# C7X256V0_CLEC_CLEC register map
Vendor: Texas Instruments
Peripheral module from a debugger description file (folder J722S).
Registers are 32-bit, read-only, reset values left out (the file's numbers can be read two ways) unless marked. A register's access mark holds for its fields unless they carry their own. Offsets are as the file gives them; lines under a group give offsets from that group; [hi:lo] are bit positions; {n}, {i} and the like mark numbered series; 'fields as' and 'values as' point back to an identical list; <NAME> marks a mode.

## C7X256V0_CLEC_CLEC
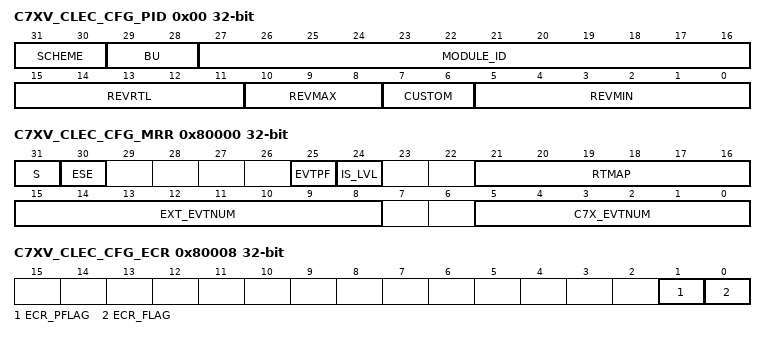
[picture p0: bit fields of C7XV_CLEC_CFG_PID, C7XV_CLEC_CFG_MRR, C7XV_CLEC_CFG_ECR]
0x00 C7XV_CLEC_CFG_PID — Revision parameters
  [31:30] SCHEME
  [29:28] BU — Scheme
  [27:16] MODULE_ID
  [15:11] REVRTL — RTL version
  [10:8] REVMAX — Major version
  [7:6] CUSTOM — Custom version
  [5:0] REVMIN — Minor version
0xA000 C7XV_CLEC_CFG_EFR — CLEC event flags
  [31:0] EVNTFR — event flag register, read only pending status of all events regardless of they are enabled or disabled, for pulse events this flag is cleared as soon as event is sent, for level events this flag is cleared when input event is deasserted, writing 1 to ECR_n register also clears this bit in case of pending pulse event, description in spec section 4.2.2
0xB000 C7XV_CLEC_CFG_EDR — CLEC dropped event flags
  [31:0] EVNTDR — dropped event flags, for input events which are pulse if events are sent back back and second event gets dropped since first event still in the pending event queue, this bit gets set indicating that an event has been dropped, it also generates dropped event interrupt, description in spec section 4.2.3
0xC000 C7XV_CLEC_CFG_GELRS rw — Event Lock reg for secure claim
  [0] LOCK — GELRS.LOCK - event lock register for secure claim
0xD000 C7XV_CLEC_CFG_GELRNS rw — Event Lock reg for non-secure claim
  [0] LOCK — GELRNS.LOCK - event lock register for non-secure claim
0x80000 C7XV_CLEC_CFG_MRR access per field — Map and routing register
  [31] S rw — MRR.S - reserved, not used for AM62A since CPU doesn't support secure mode
  [30] ESE rw — MRR.ESE - Event-Send enable. Controls whether CLEC sends this event when ESR is written or Event occurred on interrupt line
  [25] EVTPF ro — MRR.EPF - same value as EFR, read only pending status of all events regardless of they are enabled or disabled, for pulse events this flag is cleared as soon as event is sent, for level events this flag is cleared when input event is deasserted, writing 1 to ECR_n register also clears this bit in case of pending pulse event
  [24] IS_LVL rw — MRR.IS_LVL - Indicate that input event is level or pulse, event handling is different based on whether event is level or pulse
  [21:16] RTMAP rw — MRR.RTMAP - If Bit [16] = 1 Send to None, If Bit [17] = 1 and bit [16] = 0 Send to System, If [16] = 0 and [17] = 0 send to [21:18] Corepac encoded value - value 1 and 0xF are valid since there is only one CPU
  [15:8] EXT_EVTNUM rw — MRR.EXT_EVTNUM - encoded external event number, event 0- 63 SOC events, 64-95 DRU events, event 128 ARM event others are reserved for AM62A
  [5:0] C7X_EVTNUM rw — MRR.C7x_EVTNUM - C7x event number to send when this event is triggered
0x80004 C7XV_CLEC_CFG_ESR wo — Event send reg
  [31:0] ESR_N — ESR.ESR_n sends event number n if it is enabled, address offset 0x010000 * n + 0x03000
0x80008 C7XV_CLEC_CFG_ECR wo — Event clear reg
  [1] ECR_PFLAG — ECR.EDR_Clear - clears EDR flag bit when 2 is written
  [0] ECR_FLAG — ECR.EFR_Clear - clears EFR flag bit when 1 is written, also clears corresponding SOC level event if sent to system on SOCinterrupt port
